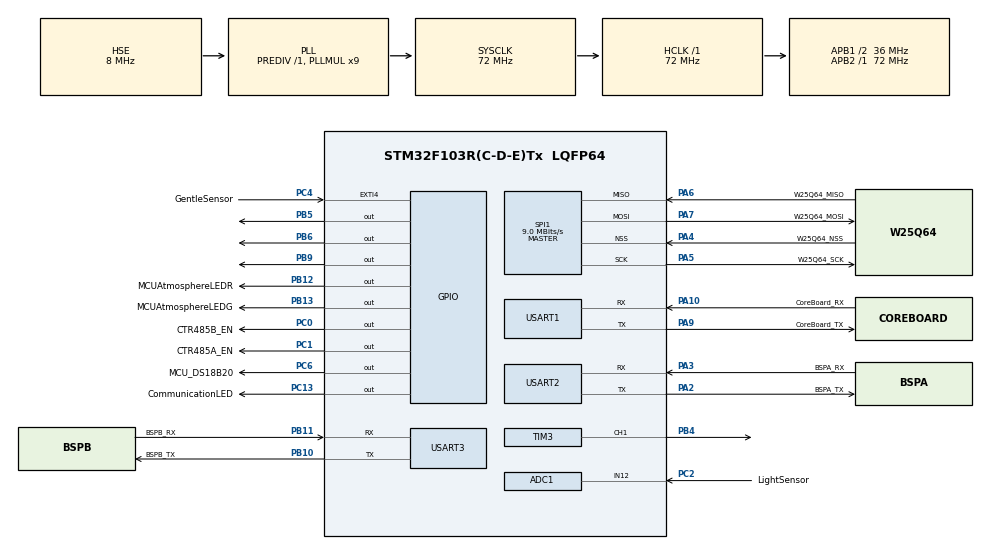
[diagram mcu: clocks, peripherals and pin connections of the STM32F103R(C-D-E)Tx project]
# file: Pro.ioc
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ADC1.Channel-0\#ChannelRegularConversion=ADC_CHANNEL_12
ADC1.Channel-1\#ChannelRegularConversion=ADC_CHANNEL_TEMPSENSOR
ADC1.ContinuousConvMode=DISABLE
ADC1.DataAlign=ADC_DATAALIGN_RIGHT
ADC1.DiscontinuousConvMode=DISABLE
ADC1.EnableAnalogWatchDog=false
ADC1.EnableRegularConversion=ENABLE
ADC1.ExternalTrigConv=ADC_SOFTWARE_START
ADC1.InjNumberOfConversion=0
ADC1.NbrOfConversion=2
ADC1.NbrOfConversionFlag=1
ADC1.Rank-0\#ChannelRegularConversion=1
ADC1.Rank-1\#ChannelRegularConversion=2
ADC1.SamplingTime-0\#ChannelRegularConversion=ADC_SAMPLETIME_239CYCLES_5
ADC1.SamplingTime-1\#ChannelRegularConversion=ADC_SAMPLETIME_239CYCLES_5
ADC1.ScanConvMode=ADC_SCAN_ENABLE
ADC1.master=1
Dma.ADC1.3.Direction=DMA_PERIPH_TO_MEMORY
Dma.ADC1.3.Instance=DMA1_Channel1
Dma.ADC1.3.MemDataAlignment=DMA_MDATAALIGN_WORD
Dma.ADC1.3.MemInc=DMA_MINC_ENABLE
Dma.ADC1.3.Mode=DMA_NORMAL
Dma.ADC1.3.PeriphDataAlignment=DMA_PDATAALIGN_WORD
Dma.ADC1.3.PeriphInc=DMA_PINC_DISABLE
Dma.ADC1.3.Priority=DMA_PRIORITY_LOW
Dma.Request0=USART1_RX
Dma.Request1=USART2_RX
Dma.Request2=USART3_RX
Dma.Request3=ADC1
Dma.USART1_RX.0.Direction=DMA_PERIPH_TO_MEMORY
Dma.USART1_RX.0.Instance=DMA1_Channel5
Dma.USART1_RX.0.MemDataAlignment=DMA_MDATAALIGN_BYTE
Dma.USART1_RX.0.MemInc=DMA_MINC_ENABLE
Dma.USART1_RX.0.Mode=DMA_NORMAL
Dma.USART1_RX.0.PeriphDataAlignment=DMA_PDATAALIGN_BYTE
Dma.USART1_RX.0.PeriphInc=DMA_PINC_DISABLE
Dma.USART1_RX.0.Priority=DMA_PRIORITY_LOW
Dma.USART2_RX.1.Direction=DMA_PERIPH_TO_MEMORY
Dma.USART2_RX.1.Instance=DMA1_Channel6
Dma.USART2_RX.1.MemDataAlignment=DMA_MDATAALIGN_BYTE
Dma.USART2_RX.1.MemInc=DMA_MINC_ENABLE
Dma.USART2_RX.1.Mode=DMA_NORMAL
Dma.USART2_RX.1.PeriphDataAlignment=DMA_PDATAALIGN_BYTE
Dma.USART2_RX.1.PeriphInc=DMA_PINC_DISABLE
Dma.USART2_RX.1.Priority=DMA_PRIORITY_LOW
Dma.USART3_RX.2.Direction=DMA_PERIPH_TO_MEMORY
Dma.USART3_RX.2.Instance=DMA1_Channel3
Dma.USART3_RX.2.MemDataAlignment=DMA_MDATAALIGN_BYTE
Dma.USART3_RX.2.MemInc=DMA_MINC_ENABLE
Dma.USART3_RX.2.Mode=DMA_NORMAL
Dma.USART3_RX.2.PeriphDataAlignment=DMA_PDATAALIGN_BYTE
Dma.USART3_RX.2.PeriphInc=DMA_PINC_DISABLE
Dma.USART3_RX.2.Priority=DMA_PRIORITY_LOW
FREERTOS.Tasks01=defaultTask,0,128,StartDefaultTask,Default,NULL
Mcu.Family=STM32F1
Mcu.Name=STM32F103R(C-D-E)Tx
Mcu.Package=LQFP64
NVIC.DMA1_Channel1_IRQn=true\:5\:0\:false\:true\:true\:10\:true\:false
NVIC.DMA1_Channel3_IRQn=true\:5\:0\:false\:true\:true\:7\:true\:false
NVIC.DMA1_Channel5_IRQn=true\:5\:0\:false\:true\:true\:8\:true\:false
NVIC.DMA1_Channel6_IRQn=true\:5\:0\:false\:true\:true\:9\:true\:false
NVIC.EXTI4_IRQn=true\:5\:0\:false\:true\:true\:1\:true\:true
NVIC.PriorityGroup=NVIC_PRIORITYGROUP_4
NVIC.TIM1_UP_IRQn=true\:0\:0\:false\:false\:true\:false\:false
NVIC.TIM4_IRQn=true\:5\:0\:false\:true\:true\:2\:true\:true
NVIC.TIM5_IRQn=true\:5\:0\:false\:true\:true\:3\:true\:true
NVIC.TimeBase=TIM1_UP_IRQn
NVIC.TimeBaseIP=TIM1
NVIC.USART1_IRQn=true\:5\:0\:false\:true\:true\:4\:true\:true
NVIC.USART2_IRQn=true\:5\:0\:false\:true\:true\:5\:true\:true
NVIC.USART3_IRQn=true\:5\:0\:false\:true\:true\:6\:true\:true
PA10.GPIO_Label=CoreBoard_RX
PA10.Mode=Asynchronous
PA10.Signal=USART1_RX
PA13.Mode=Serial_Wire
PA13.Signal=SYS_JTMS-SWDIO
PA14.Mode=Serial_Wire
PA14.Signal=SYS_JTCK-SWCLK
PA2.GPIO_Label=BSPA_TX
PA2.Mode=Asynchronous
PA2.Signal=USART2_TX
PA3.GPIO_Label=BSPA_RX
PA3.Mode=Asynchronous
PA3.Signal=USART2_RX
PA4.GPIO_Label=W25Q64_NSS
PA4.Mode=NSS_Signal_Hard_Input
PA4.Signal=SPI1_NSS
PA5.GPIO_Label=W25Q64_SCK
PA5.Mode=Full_Duplex_Master
PA5.Signal=SPI1_SCK
PA6.GPIO_Label=W25Q64_MISO
PA6.Mode=Full_Duplex_Master
PA6.Signal=SPI1_MISO
PA7.GPIO_Label=W25Q64_MOSI
PA7.Mode=Full_Duplex_Master
PA7.Signal=SPI1_MOSI
PA9.GPIO_Label=CoreBoard_TX
PA9.Mode=Asynchronous
PA9.Signal=USART1_TX
PB10.GPIO_Label=BSPB_TX
PB10.Mode=Asynchronous
PB10.Signal=USART3_TX
PB11.GPIO_Label=BSPB_RX
PB11.Mode=Asynchronous
PB11.Signal=USART3_RX
PB12.GPIO_Label=MCUAtmosphereLEDR
PB12.Signal=GPIO_Output
PB13.GPIO_Label=MCUAtmosphereLEDG
PB13.Signal=GPIO_Output
PB4.Signal=S_TIM3_CH1
PB5.Signal=GPIO_Output
PB6.Signal=GPIO_Output
PB9.Signal=GPIO_Output
PC0.GPIO_Label=CTR485B_EN
PC0.Signal=GPIO_Output
PC1.GPIO_Label=CTR485A_EN
PC1.Signal=GPIO_Output
PC13-TAMPER-RTC.GPIO_Label=CommunicationLED
PC13-TAMPER-RTC.Signal=GPIO_Output
PC2.GPIO_Label=LightSensor
PC2.Signal=ADCx_IN12
PC4.GPIO_Label=GentleSensor
PC4.Signal=GPXTI4
PC6.GPIO_Label=MCU_DS18B20
PC6.Signal=GPIO_Output
PD0-OSC_IN.Mode=HSE-External-Oscillator
PD0-OSC_IN.Signal=RCC_OSC_IN
PD1-OSC_OUT.Mode=HSE-External-Oscillator
PD1-OSC_OUT.Signal=RCC_OSC_OUT
ProjectManager.HeapSize=0x200
ProjectManager.StackSize=0x400
ProjectManager.TargetToolchain=Makefile
RCC.ADCPresc=RCC_ADCPCLK2_DIV6
RCC.AHBFreq_Value=72000000
RCC.APB1CLKDivider=RCC_HCLK_DIV2
RCC.APB1Freq_Value=36000000
RCC.APB1TimFreq_Value=72000000
RCC.APB2Freq_Value=72000000
RCC.APB2TimFreq_Value=72000000
RCC.HCLKFreq_Value=72000000
RCC.PLLMUL=RCC_PLL_MUL9
RCC.PLLSourceVirtual=RCC_PLLSOURCE_HSE
RCC.SYSCLKFreq_VALUE=72000000
RCC.SYSCLKSource=RCC_SYSCLKSOURCE_PLLCLK
RCC.USBFreq_Value=72000000
SH.ADCx_IN12.0=ADC1_IN12,IN12
SH.S_TIM3_CH1.0=TIM3_CH1,PWM Generation1 CH1
SPI1.BaudRatePrescaler=SPI_BAUDRATEPRESCALER_8
SPI1.CalculateBaudRate=9.0 MBits/s
SPI1.Direction=SPI_DIRECTION_2LINES
SPI1.Mode=SPI_MODE_MASTER
SPI1.VirtualNSS=VM_NSSHARD
SPI1.VirtualType=VM_MASTER
TIM3.Channel-PWM\ Generation1\ CH1=TIM_CHANNEL_1
USART1.VirtualMode=VM_ASYNC
USART2.VirtualMode=VM_ASYNC
USART3.VirtualMode=VM_ASYNC
VP_ADC1_TempSens_Input.Mode=IN-TempSens
VP_FREERTOS_VS_ENABLE.Mode=Enabled
VP_SYS_VS_tim1.Mode=TIM1
VP_TIM3_VS_ClockSourceINT.Mode=Internal
VP_TIM4_VS_ClockSourceINT.Mode=Internal
VP_TIM5_VS_ClockSourceINT.Mode=Internal
board=custom

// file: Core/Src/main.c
/**
  ******************************************************************************
  * @file           : main.c
  * @brief          : Main program body
  ******************************************************************************
  * This notice applies to any and all portions of this file
  * that are not between comment pairs USER CODE BEGIN and
  * USER CODE END. Other portions of this file, whether
  * inserted by the user or by software development tools
  * are owned by their respective copyright owners.
  *
  * Copyright (c) 2018 STMicroelectronics International N.V.
  * All rights reserved.
  *
  * Redistribution and use in source and binary forms, with or without
  * modification, are permitted, provided that the following conditions are met:
  *
  * 1. Redistribution of source code must retain the above copyright notice,
  *    this list of conditions and the following disclaimer.
  * 2. Redistributions in binary form must reproduce the above copyright notice,
  *    this list of conditions and the following disclaimer in the documentation
  *    and/or other materials provided with the distribution.
  * 3. Neither the name of STMicroelectronics nor the names of other
  *    contributors to this software may be used to endorse or promote products
  *    derived from this software without specific written permission.
  * 4. This software, including modifications and/or derivative works of this
  *    software, must execute solely and exclusively on microcontroller or
  *    microprocessor devices manufactured by or for STMicroelectronics.
  * 5. Redistribution and use of this software other than as permitted under
  *    this license is void and will automatically terminate your rights under
  *    this license.
  *
  * THIS SOFTWARE IS PROVIDED BY STMICROELECTRONICS AND CONTRIBUTORS "AS IS"
  * AND ANY EXPRESS, IMPLIED OR STATUTORY WARRANTIES, INCLUDING, BUT NOT
  * LIMITED TO, THE IMPLIED WARRANTIES OF MERCHANTABILITY, FITNESS FOR A
  * PARTICULAR PURPOSE AND NON-INFRINGEMENT OF THIRD PARTY INTELLECTUAL PROPERTY
  * RIGHTS ARE DISCLAIMED TO THE FULLEST EXTENT PERMITTED BY LAW. IN NO EVENT
  * SHALL STMICROELECTRONICS OR CONTRIBUTORS BE LIABLE FOR ANY DIRECT, INDIRECT,
  * INCIDENTAL, SPECIAL, EXEMPLARY, OR CONSEQUENTIAL DAMAGES (INCLUDING, BUT NOT
  * LIMITED TO, PROCUREMENT OF SUBSTITUTE GOODS OR SERVICES; LOSS OF USE, DATA,
  * OR PROFITS; OR BUSINESS INTERRUPTION) HOWEVER CAUSED AND ON ANY THEORY OF
  * LIABILITY, WHETHER IN CONTRACT, STRICT LIABILITY, OR TORT (INCLUDING
  * NEGLIGENCE OR OTHERWISE) ARISING IN ANY WAY OUT OF THE USE OF THIS SOFTWARE,
  * EVEN IF ADVISED OF THE POSSIBILITY OF SUCH DAMAGE.
  *
  ******************************************************************************
  */
#include "main.h"
#include "stm32f1xx_hal.h"
#include "cmsis_os.h"
#include "adc.h"
#include "dma.h"
#include "spi.h"
#include "tim.h"
#include "usart.h"
#include "gpio.h"

/* USER CODE BEGIN PV */
/* Private variables ---------------------------------------------------------*/

/* USER CODE END PV */

void SystemClock_Config(void);
void MX_FREERTOS_Init(void);
static void MX_NVIC_Init(void);

/* USER CODE BEGIN PFP */
/* Private function prototypes -----------------------------------------------*/

/* USER CODE END PFP */

int main(void)
{

  /* MCU Configuration----------------------------------------------------------*/

  /* Reset of all peripherals, Initializes the Flash interface and the Systick. */
  HAL_Init();

  /* Configure the system clock */
  SystemClock_Config();

  /* Initialize all configured peripherals */
  MX_GPIO_Init();
  MX_DMA_Init();
  MX_USART1_UART_Init();
  MX_USART2_UART_Init();
  MX_USART3_UART_Init();
  MX_SPI1_Init();
  MX_ADC1_Init();
  MX_TIM3_Init();
  MX_TIM4_Init();
  MX_TIM5_Init();

  /* Initialize interrupts */
  MX_NVIC_Init();
  /* USER CODE BEGIN 2 */
<<<<<<< HEAD
  //DS_CoreBoardProtocolInit();
  //DS_BSPABoardProtocolInit();
  //DS_BSPBBoardProtocolInit();
  //printf("Enter FreeRTOS\r\n");
=======

>>>>>>> parent of 556606d... add usart handle
  /* USER CODE END 2 */

  /* Call init function for freertos objects (in freertos.c) */
  //MX_FREERTOS_Init();

  /* Start scheduler */
  //osKernelStart();

  /* We should never get here as control is now taken by the scheduler */

  /* Infinite loop */
  while (1)
  {

  /* USER CODE BEGIN 3 */
  HAL_UART_Transmit(&huart1, (uint8_t *)"Hellow Main\r\n", 11, 0x0F);
  HAL_Delay(1000);

  }
  /* USER CODE END 3 */

}

void SystemClock_Config(void)
{

  RCC_OscInitTypeDef RCC_OscInitStruct;
  RCC_ClkInitTypeDef RCC_ClkInitStruct;
  RCC_PeriphCLKInitTypeDef PeriphClkInit;

    /**Initializes the CPU, AHB and APB busses clocks
    */
  RCC_OscInitStruct.OscillatorType = RCC_OSCILLATORTYPE_HSE;
  RCC_OscInitStruct.HSEState = RCC_HSE_ON;
  RCC_OscInitStruct.HSEPredivValue = RCC_HSE_PREDIV_DIV1;
  RCC_OscInitStruct.HSIState = RCC_HSI_ON;
  RCC_OscInitStruct.PLL.PLLState = RCC_PLL_ON;
  RCC_OscInitStruct.PLL.PLLSource = RCC_PLLSOURCE_HSE;
  RCC_OscInitStruct.PLL.PLLMUL = RCC_PLL_MUL9;
  if (HAL_RCC_OscConfig(&RCC_OscInitStruct) != HAL_OK)
  {
    _Error_Handler(__FILE__, __LINE__);
  }

    /**Initializes the CPU, AHB and APB busses clocks
    */
  RCC_ClkInitStruct.ClockType = RCC_CLOCKTYPE_HCLK|RCC_CLOCKTYPE_SYSCLK
                              |RCC_CLOCKTYPE_PCLK1|RCC_CLOCKTYPE_PCLK2;
  RCC_ClkInitStruct.SYSCLKSource = RCC_SYSCLKSOURCE_PLLCLK;
  RCC_ClkInitStruct.AHBCLKDivider = RCC_SYSCLK_DIV1;
  RCC_ClkInitStruct.APB1CLKDivider = RCC_HCLK_DIV2;
  RCC_ClkInitStruct.APB2CLKDivider = RCC_HCLK_DIV1;

  if (HAL_RCC_ClockConfig(&RCC_ClkInitStruct, FLASH_LATENCY_2) != HAL_OK)
  {
    _Error_Handler(__FILE__, __LINE__);
  }

  PeriphClkInit.PeriphClockSelection = RCC_PERIPHCLK_ADC;
  PeriphClkInit.AdcClockSelection = RCC_ADCPCLK2_DIV6;
  if (HAL_RCCEx_PeriphCLKConfig(&PeriphClkInit) != HAL_OK)
  {
    _Error_Handler(__FILE__, __LINE__);
  }

    /**Configure the Systick interrupt time
    */
  HAL_SYSTICK_Config(HAL_RCC_GetHCLKFreq()/1000);

    /**Configure the Systick
    */
  HAL_SYSTICK_CLKSourceConfig(SYSTICK_CLKSOURCE_HCLK);

  /* SysTick_IRQn interrupt configuration */
  HAL_NVIC_SetPriority(SysTick_IRQn, 15, 0);
}

/**
  * @brief NVIC Configuration.
  * @retval None
  */
static void MX_NVIC_Init(void)
{
  /* EXTI4_IRQn interrupt configuration */
  HAL_NVIC_SetPriority(EXTI4_IRQn, 5, 0);
  HAL_NVIC_EnableIRQ(EXTI4_IRQn);
  /* TIM4_IRQn interrupt configuration */
  HAL_NVIC_SetPriority(TIM4_IRQn, 5, 0);
  HAL_NVIC_EnableIRQ(TIM4_IRQn);
  /* TIM5_IRQn interrupt configuration */
  HAL_NVIC_SetPriority(TIM5_IRQn, 5, 0);
  HAL_NVIC_EnableIRQ(TIM5_IRQn);
  /* USART1_IRQn interrupt configuration */
  HAL_NVIC_SetPriority(USART1_IRQn, 5, 0);
  HAL_NVIC_EnableIRQ(USART1_IRQn);
  /* USART2_IRQn interrupt configuration */
  HAL_NVIC_SetPriority(USART2_IRQn, 5, 0);
  HAL_NVIC_EnableIRQ(USART2_IRQn);
  /* USART3_IRQn interrupt configuration */
  HAL_NVIC_SetPriority(USART3_IRQn, 5, 0);
  HAL_NVIC_EnableIRQ(USART3_IRQn);
  /* DMA1_Channel3_IRQn interrupt configuration */
  HAL_NVIC_SetPriority(DMA1_Channel3_IRQn, 5, 0);
  HAL_NVIC_EnableIRQ(DMA1_Channel3_IRQn);
  /* DMA1_Channel5_IRQn interrupt configuration */
  HAL_NVIC_SetPriority(DMA1_Channel5_IRQn, 5, 0);
  HAL_NVIC_EnableIRQ(DMA1_Channel5_IRQn);
  /* DMA1_Channel6_IRQn interrupt configuration */
  HAL_NVIC_SetPriority(DMA1_Channel6_IRQn, 5, 0);
  HAL_NVIC_EnableIRQ(DMA1_Channel6_IRQn);
  /* DMA1_Channel1_IRQn interrupt configuration */
  HAL_NVIC_SetPriority(DMA1_Channel1_IRQn, 5, 0);
  HAL_NVIC_EnableIRQ(DMA1_Channel1_IRQn);
}

void HAL_TIM_PeriodElapsedCallback(TIM_HandleTypeDef *htim)
{
  if (htim->Instance == TIM1) {
    HAL_IncTick();
  }
}

void _Error_Handler(char *file, int line)
{
  while(1)
  {
  }
}

/************************ (C) COPYRIGHT STMicroelectronics *****END OF FILE****/
